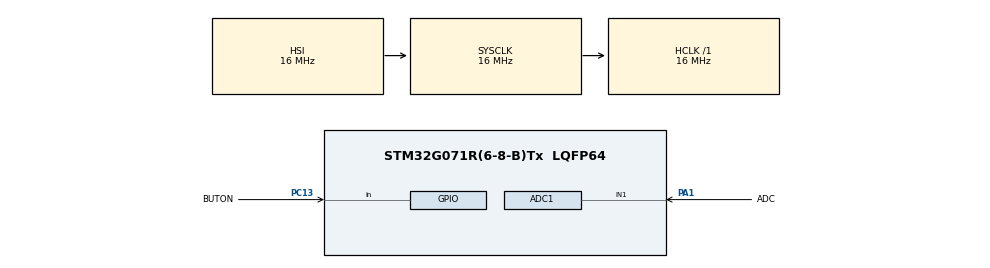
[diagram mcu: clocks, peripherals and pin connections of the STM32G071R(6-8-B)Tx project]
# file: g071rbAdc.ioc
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Mcu.Family=STM32G0
RCC.CortexFreq_Value=16000000
ADC1.Rank-0\#ChannelRegularConversion=1
ADC1.ContinuousConvMode=ENABLE
PC13.Signal=GPIO_Input
PA14-BOOT0.Mode=Serial_Wire
RCC.EXTERNAL_CLOCK_VALUE=12288000
PC15-OSC32_OUT\ (PC15).Signal=RCC_OSC32_OUT
PC15-OSC32_OUT\ (PC15).Mode=LSE-External-Oscillator
PC13.GPIO_Label=BUTON
PF0-OSC_IN\ (PF0).Signal=RCC_OSC_IN
ProjectManager.StackSize=0x400
PC14-OSC32_IN\ (PC14).Mode=LSE-External-Oscillator
PF0-OSC_IN\ (PF0).Mode=HSE-External-Clock-Source
PA13.Signal=SYS_SWDIO
ProjectManager.TargetToolchain=STM32CubeIDE
RCC.HCLKFreq_Value=16000000
PA1.Signal=ADC1_IN1
RCC.AHBFreq_Value=16000000
PA14-BOOT0.Signal=SYS_SWCLK
ADC1.Channel-0\#ChannelRegularConversion=ADC_CHANNEL_1
RCC.HSE_VALUE=8000000
board=NUCLEO-G071RB
RCC.VCOOutputFreq_Value=128000000
PA1.Mode=IN1
PA1.GPIO_Label=ADC
VP_SYS_VS_DBSignals.Mode=DisableDeadBatterySignals
PA13.Mode=Serial_Wire
Mcu.Name=STM32G071R(6-8-B)Tx
ADC1.SamplingTime-0\#ChannelRegularConversion=ADC_SAMPLINGTIME_COMMON_1
ADC1.SelectedChannel=ADC_CHANNEL_1
RCC.SYSCLKFreq_VALUE=16000000
Mcu.Package=LQFP64
ADC1.master=1
PC14-OSC32_IN\ (PC14).Signal=RCC_OSC32_IN
ProjectManager.HeapSize=0x200
RCC.HSI_VALUE=16000000
ADC1.NbrOfConversionFlag=1

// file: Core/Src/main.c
/* USER CODE BEGIN Header */
/**
  ******************************************************************************
  * @file           : main.c
  * @brief          : Main program body
  ******************************************************************************
  * @attention
  *
  * <h2><center>&copy; Copyright (c) 2021 STMicroelectronics.
  * All rights reserved.</center></h2>
  *
  * This software component is licensed by ST under BSD 3-Clause license,
  * the "License"; You may not use this file except in compliance with the
  * License. You may obtain a copy of the License at:
  *                        opensource.org/licenses/BSD-3-Clause
  *
  ******************************************************************************
  */
/* USER CODE END Header */
#include "main.h"

ADC_HandleTypeDef hadc1;

/* USER CODE BEGIN PV */
/* adc okuması yapmak için gereken değerin tanımı */
uint16_t adc;
/* mavi buton okuması için gereken değerin tanımı */
int buton;
/* USER CODE END PV */

void SystemClock_Config(void);
static void MX_GPIO_Init(void);
static void MX_ADC1_Init(void);

int main(void)
{

  /* MCU Configuration--------------------------------------------------------*/

  /* Reset of all peripherals, Initializes the Flash interface and the Systick. */
  HAL_Init();

  /* Configure the system clock */
  SystemClock_Config();

  /* Initialize all configured peripherals */
  MX_GPIO_Init();
  MX_ADC1_Init();

  /* Infinite loop */
  /* USER CODE BEGIN WHILE */
  while (1)
  {
	  /* gpio kullanarak buton okuma */
	  buton=!HAL_GPIO_ReadPin(BUTON_GPIO_Port, BUTON_Pin);
	  /* adc üzerinden değer okuma */
	  adc=HAL_ADC_GetValue(&hadc1);
	  /* bekleme süresi */
	  HAL_Delay(500);
    /* USER CODE END WHILE */

  }
}

void SystemClock_Config(void)
{
  RCC_OscInitTypeDef RCC_OscInitStruct = {0};
  RCC_ClkInitTypeDef RCC_ClkInitStruct = {0};
  RCC_PeriphCLKInitTypeDef PeriphClkInit = {0};

  /** Configure the main internal regulator output voltage
  */
  HAL_PWREx_ControlVoltageScaling(PWR_REGULATOR_VOLTAGE_SCALE1);
  /** Initializes the RCC Oscillators according to the specified parameters
  * in the RCC_OscInitTypeDef structure.
  */
  RCC_OscInitStruct.OscillatorType = RCC_OSCILLATORTYPE_HSI;
  RCC_OscInitStruct.HSIState = RCC_HSI_ON;
  RCC_OscInitStruct.HSIDiv = RCC_HSI_DIV1;
  RCC_OscInitStruct.HSICalibrationValue = RCC_HSICALIBRATION_DEFAULT;
  RCC_OscInitStruct.PLL.PLLState = RCC_PLL_NONE;
  if (HAL_RCC_OscConfig(&RCC_OscInitStruct) != HAL_OK)
  {
    Error_Handler();
  }
  /** Initializes the CPU, AHB and APB buses clocks
  */
  RCC_ClkInitStruct.ClockType = RCC_CLOCKTYPE_HCLK|RCC_CLOCKTYPE_SYSCLK
                              |RCC_CLOCKTYPE_PCLK1;
  RCC_ClkInitStruct.SYSCLKSource = RCC_SYSCLKSOURCE_HSI;
  RCC_ClkInitStruct.AHBCLKDivider = RCC_SYSCLK_DIV1;
  RCC_ClkInitStruct.APB1CLKDivider = RCC_HCLK_DIV1;

  if (HAL_RCC_ClockConfig(&RCC_ClkInitStruct, FLASH_LATENCY_0) != HAL_OK)
  {
    Error_Handler();
  }
  /** Initializes the peripherals clocks
  */
  PeriphClkInit.PeriphClockSelection = RCC_PERIPHCLK_ADC;
  PeriphClkInit.AdcClockSelection = RCC_ADCCLKSOURCE_SYSCLK;
  if (HAL_RCCEx_PeriphCLKConfig(&PeriphClkInit) != HAL_OK)
  {
    Error_Handler();
  }
}

static void MX_ADC1_Init(void)
{

  ADC_ChannelConfTypeDef sConfig = {0};

  /** Configure the global features of the ADC (Clock, Resolution, Data Alignment and number of conversion)
  */
  hadc1.Instance = ADC1;
  hadc1.Init.ClockPrescaler = ADC_CLOCK_SYNC_PCLK_DIV2;
  hadc1.Init.Resolution = ADC_RESOLUTION_12B;
  hadc1.Init.DataAlign = ADC_DATAALIGN_RIGHT;
  hadc1.Init.ScanConvMode = ADC_SCAN_DISABLE;
  hadc1.Init.EOCSelection = ADC_EOC_SINGLE_CONV;
  hadc1.Init.LowPowerAutoWait = DISABLE;
  hadc1.Init.LowPowerAutoPowerOff = DISABLE;
  hadc1.Init.ContinuousConvMode = ENABLE;
  hadc1.Init.NbrOfConversion = 1;
  hadc1.Init.DiscontinuousConvMode = DISABLE;
  hadc1.Init.ExternalTrigConv = ADC_SOFTWARE_START;
  hadc1.Init.ExternalTrigConvEdge = ADC_EXTERNALTRIGCONVEDGE_NONE;
  hadc1.Init.DMAContinuousRequests = DISABLE;
  hadc1.Init.Overrun = ADC_OVR_DATA_PRESERVED;
  hadc1.Init.SamplingTimeCommon1 = ADC_SAMPLETIME_1CYCLE_5;
  hadc1.Init.SamplingTimeCommon2 = ADC_SAMPLETIME_1CYCLE_5;
  hadc1.Init.OversamplingMode = DISABLE;
  hadc1.Init.TriggerFrequencyMode = ADC_TRIGGER_FREQ_HIGH;
  if (HAL_ADC_Init(&hadc1) != HAL_OK)
  {
    Error_Handler();
  }
  /** Configure Regular Channel
  */
  sConfig.Channel = ADC_CHANNEL_1;
  sConfig.Rank = ADC_REGULAR_RANK_1;
  sConfig.SamplingTime = ADC_SAMPLINGTIME_COMMON_1;
  if (HAL_ADC_ConfigChannel(&hadc1, &sConfig) != HAL_OK)
  {
    Error_Handler();
  }

}

static void MX_GPIO_Init(void)
{
  GPIO_InitTypeDef GPIO_InitStruct = {0};

  /* GPIO Ports Clock Enable */
  __HAL_RCC_GPIOC_CLK_ENABLE();
  __HAL_RCC_GPIOF_CLK_ENABLE();
  __HAL_RCC_GPIOA_CLK_ENABLE();

  /*Configure GPIO pin : BUTON_Pin */
  GPIO_InitStruct.Pin = BUTON_Pin;
  GPIO_InitStruct.Mode = GPIO_MODE_INPUT;
  GPIO_InitStruct.Pull = GPIO_NOPULL;
  HAL_GPIO_Init(BUTON_GPIO_Port, &GPIO_InitStruct);

}

void Error_Handler(void)
{
  __disable_irq();
  while (1)
  {
  }
}

/************************ (C) COPYRIGHT STMicroelectronics *****END OF FILE****/
